# netx90_app register map
File version: 1.0
CPU: CM4 r0p1, little endian, MPU, FPU, 4 interrupt priority bits, 78 interrupts
Registers are 32-bit, read-write, reset 0x0 unless marked. A register's access mark holds for its fields unless they carry their own. Offsets are from the block's base; [hi:lo] are bit positions; {n}, {i} and the like mark numbered series.

## dmac_app_ch[{n}] — dmac_app_ch0
Base 0xFF800100; array of 4, step 0x20
0x00 dmac_chsrc_ad — channel source address registers
  [31:0] DMACCHSRCADDR — DMA source address
0x04 dmac_chdest_ad — channel destination address registers
  [31:0] DMACCHDESTADDR — DMA destination address
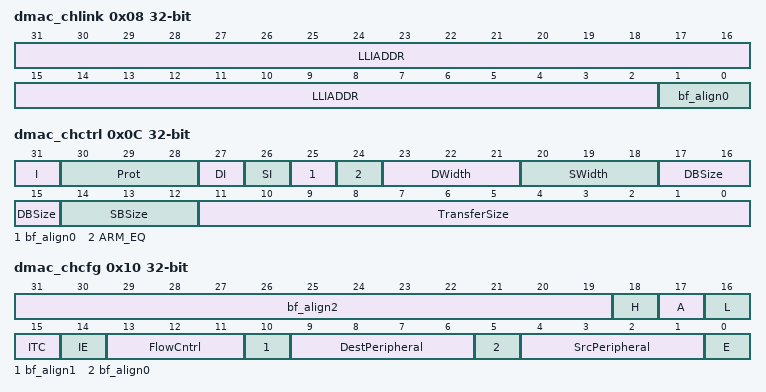
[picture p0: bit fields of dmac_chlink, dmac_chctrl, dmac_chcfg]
0x08 dmac_chlink (reset mask 0xFFFFFFFC) — channel linked list item register
  [31:2] LLIADDR — Linked list item. Bits [31:2] of the address for the next LLI. Address bits [1:0] are 0.
  [1:0] bf_align0 — bitField alignment value for aeabi compatibility
0x0C dmac_chctrl (reset mask 0xFDFFFFFF) — channel control registers
  [31] I — Terminal count interrupt enable bit. It controls whether the current LLI is expected to trigger the terminal count interrupt.
  [30:28] Prot — Protection.
  [27] DI — Destination increment. When set the destination address is incremented after each transfer.
  [26] SI — Source increment. When set the source address is incremented after each transfer.
  [25] bf_align0 — bitField alignment value for aeabi compatibility
  [24] ARM_EQ — Set equal behaviour to arm implementation This bit should always be set to 1 (default of 0 is from historical reasons). This bit changes 2 behavioural details: 1. ARM_EQ=1: ignore single requests in DMA-controlled Memory-to-Peripheral accesses. ARM_EQ=0: handle single requests like burst requests (in this case DBSize should be 1 access). Note: In DMA-controlled Memory-to-Peripheral mode only burst request signals are allowed. The behaviour of single requests (from peripheral to DMAC) is not defined. Modules generating single requests anyways might use ARM_EQ=0 in combination with DBSize=000. 2. ARM_EQ=1: Always read 0 from TransferSize in this register. ARM_EQ=0: Read some internal value for debug purposes
  [23:21] DWidth — Destination transfer width: The source and destination widths can be different from each other. The hardware automatically packs and unpacks the data as required. _________________________ bit_value data_width ------------------------- 000 8 bit 001 16 bit 010 32 bit =========================
  [20:18] SWidth — Source transfer width: The source and destination widths can be different from each other. The hardware automatically packs and unpacks the data as required. _________________________ bit_value data_width ------------------------- 000 8 bit 001 16 bit 010 32 bit =========================
  [17:15] DBSize — Destination burst size: Indicates the number of transfers which make up a destination burst transfer request. This value must be set to the burst size of the destination peripheral, or if the destination is memory, to the memory boundary size. The burst size is the amount of data that is transferred when the DMACxBREQ signal goes active in the destination peripheral. The burst size is not related to the AHB HBURST signal. Note: If flow controller is DMAC and destination is a peripheral, only bursts are transferred to the peripheral (DMACxSREQ is ignored if set by peripheral). The source burst size has no such limitation. ________________________________ bit_value burst_transfer_size -------------------------------- 000 1 001 4 010 8 011 16 100 32 101 64 110 128 111 256 ================================
  [14:12] SBSize — Source burst size: Indicates the number of transfers which make up a source burst. This value must be set to the burst size of the source peripheral, or if the source is memory, to the memory boundary size. The burst size is the amount of data that is transferred when the DMACxBREQ signal goes active in the source peripheral. The burst size is not related to the AHB HBURST signal. ________________________________ bit_value burst_transfer_size -------------------------------- 000 1 001 4 010 8 011 16 100 32 101 64 110 128 111 256 ================================
  [11:0] TransferSize — Transfer size: For writes, this field indicates the number of (Source width) transfers to perform when the DMAC is the flow controller. For reads, the transfer size indicates the number of transfers completed on the destination bus. Reading the register when the channel is active does not give useful information, as by the time that the software has processed the value read, the channel might have progressed. It is intended to be used only when a channel is enabled and then disabled. If the DMAC controller is not the flow controller the transfer size should be set to 0.
0x10 dmac_chcfg (reset mask 0x7FBDF) — channel configuration registers
  [31:19] bf_align2 — bitField alignment value for aeabi compatibility
  [18] H — Halt: 0 = allow DMA requests 1 = ignore further source DMA requests. The contents of the channels FIFO are drained. This value can be used with the Active and Channel Enable bits to cleanly disable a DMA channel.
  [17] A — Active: 0 = there is no data in the FIFO of the channel 1 = the FIFO of the channel has data. (ro) This value can be used with the Halt and Channel Enable bits to cleanly disable a DMA channel.
  [16] L — Lock. When set this bit enables locked transfers.
  [15] ITC — Terminal count interrupt mask. When cleared this bit masks out the terminal count interrupt of the relevant channel.
  [14] IE — Interrupt error mask. When cleared this bit masks out the error interrupt of the relevant channel.
  [13:11] FlowCntrl — Flow control and transfer type. This value is used to indicate the flow controller and transfer type. The flow controller can be the DMAC, the source peripheral, or the destination peripheral. The transfer type can be either memory-to-memory, memory-to-peripheral, peripheral-to-memory, or peripheral-to-peripheral. _______________________________________________________________________ bit_value transfer_type controller ----------------------------------------------------------------------- 000 Memory-to-memory DMAC 001 Memory-to-peripheral DMAC 010 Peripheral-to-memorys DMAC 011 Source peripheral-to-destination peripheral DMAC (not supported in netX system) 100 Source peripheral-to-destination peripheral Destination peripheral (not supported in netX system) 101 Memory-to-peripheral Peripheral 110 Peripheral-to-memory Peripheral 111 Source peripheral-to-destination peripheral Source peripheral (not supported in netX system) ======================================================================== Note: Peripheral-to-peripheral transfers are configurable, but not supported in the netX system. Don't use these three modes.
  [10] bf_align1 — bitField alignment value for aeabi compatibility
  [9:6] DestPeripheral — Destination peripheral. This value selects the DMA destination request peripheral. This field is ignored if the destination of the transfer is to memory. For mapping of peripheral to value see 'SrcPeripheral' bit-field in this register.
  [5] bf_align0 — bitField alignment value for aeabi compatibility
  [4:1] SrcPeripheral — Source peripheral. This value selects the DMA source request peripheral. This field is ignored if the source of the transfer is from memory. Note: The mapping of peripherals to App-side DMAC inputs is done within the DMAC_MUX_APP module. See 'dmac_mux_peripheral_input_sel*' registers for default mapping / current mapping. { | | value Com-side App-side 0 uart_rx dmac_mux_peripheral_input_sel0 1 uart_tx dmac_mux_peripheral_input_sel1 2 i2c0_com_master dmac_mux_peripheral_input_sel2 3 i2c0_com_slave dmac_mux_peripheral_input_sel3 4 i2c1_com_master dmac_mux_peripheral_input_sel4 5 i2c1_com_slave dmac_mux_peripheral_input_sel5 6 sqi_rx dmac_mux_peripheral_input_sel6 7 sqi_tx dmac_mux_peripheral_input_sel7 8 eth_rx reserved 9 eth_tx reserved 10 hash reserved 11 aes_in reserved 12 aes_out reserved 13 reserved reserved 14 reserved reserved 15 reserved reserved }
  [0] E — Channel enable. Reading this bit indicates whether a channel is currently enabled or disabled: 0 = channel disabled 1 = channel enabled. The Channel Enable bit status can also be found by reading the DMACEnbldChns register. A channel is enabled by setting this bit. Before enabling a single channel the DMA controller must be enabled globally by setting the DMACENABLE bit in the dmac_config register. Enabling a channel while the controller is disabled leads to undefined behaviour. A channel can be disabled by clearing the Enable bit. This causes the current AHB transfer (if one is in progress) to complete and the channel is then disabled. Any data in the channels FIFO is lost. Restarting the channel by simply setting the Channel Enable bit has unpredictable effects and the channel must be fully re-initialized. The channel is also disabled, and Channel Enable bit cleared, when the last LLI is reached or if a channel error is encountered. If a channel has to be disabled without losing data in a channels FIFO the Halt bit must be set so that further DMA requests are ignored. The Active bit must then be polled until it reaches 0, indicating that there is no data left in the channels FIFO. Finally the Channel Enable bit can be cleared.
